# MU3E_ORDERED_PRIORITY_QUEUE register map
Vendor: Mu3e; Series: MU3E_FPGA_IP; File version: 26.5.1.0509
CMSIS-SVD description of the ordered_priority_queue CSR aperture. BaseAddress is 0 because this file describes the relative CSR aperture of the IP; system integration supplies the live slave base address.
Registers are 32-bit, read-only, reset 0x0 unless marked. A register's access mark holds for its fields unless they carry their own. Offsets are from the block's base; lines under a group give offsets from that group; [hi:lo] are bit positions; {n}, {i} and the like mark numbered series; 'fields as' and 'values as' point back to an identical list; <NAME> marks a mode.

## Memory map
0x00000000 ORDERED_PRIORITY_QUEUE_CSR size 0x800 — Relative CSR aperture for the ordered priority queue. Register offsets are byte offsets matching the RTL word-addressed Avalon-MM map multiplied by four.

## ORDERED_PRIORITY_QUEUE_CSR — Relative CSR aperture for the ordered priority queue. Register offsets are byte offsets matching the RTL word-addressed Avalon-MM map multiplied by four.
Base 0x00000000
0x00 UID reset 0x4F50514D — Software-visible IP identifier. Default ASCII "OPQM".
  [31:0] value — Compile-time or integration-time UID word. Default ASCII "OPQM".
0x04 META rw — Read-multiplexed metadata word. Write [1:0] selects VERSION, DATE, GIT, or INSTANCE_ID; reads return the selected page payload.
  [31:0] page_sel_or_payload — Writes use [1:0] as the metadata page selector; reads return the selected 32-bit payload.
0x08 LANE_MASK rw — Software lane mask applied at packet boundaries. Low CAP.N_LANE bits are implemented.
  [15:0] lane_mask — Bit i masks lane i after the in-flight packet drains.
0x0C CTRL wo — Write-only control pulses.
  [0] clear_counters rw write-1-sets — Write one to clear all software-visible counters and sticky handle FIFO overflow status.
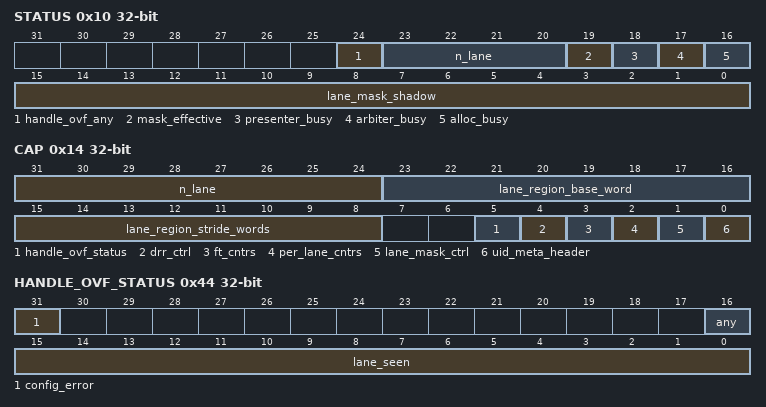
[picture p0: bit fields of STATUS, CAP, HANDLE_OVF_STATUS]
0x10 STATUS — Lane-mask shadow, busy flags, effective-mask status, lane count, and handle FIFO overflow summary.
  [24] handle_ovf_any — Sticky high after any handle FIFO overflow event.
  [23:20] n_lane — Instantiated lane count.
  [19] mask_effective — At least one lane is currently blocked at the packet-boundary mask gate.
  [18] presenter_busy — Egress presenter has a valid beat pending or in flight.
  [17] arbiter_busy — Page-RAM write-port arbiter is active.
  [16] alloc_busy — Page allocator is active.
  [15:0] lane_mask_shadow — Software-programmed lane mask shadow. Only low CAP.N_LANE bits are active.
0x14 CAP — Capability summary and CSR lane-region geometry.
  [31:24] n_lane — Number of instantiated ingress lanes.
  [23:16] lane_region_base_word — Base word address of the per-lane CSR region. Current RTL returns 0x40.
  [15:8] lane_region_stride_words — Per-lane CSR region stride in 32-bit words. Current RTL returns 0x10.
  [5] handle_ovf_status — Handle FIFO overflow status, counters, and max occupancy registers are implemented.
  [4] drr_ctrl — DRR allowance programming and observability are implemented.
  [3] ft_cntrs — Frame-table counters are implemented.
  [2] per_lane_cntrs — Per-lane counters are implemented.
  [1] lane_mask_ctrl — Software lane masking is implemented.
  [0] uid_meta_header — Common Mu3e UID and META header is implemented.
0x20 FT_WR_HDR — Headers committed into frame-table ownership.
  [31:0] value
0x24 FT_WR_SHD — Subheaders committed into frame-table ownership.
  [31:0] value
0x28 FT_WR_HIT — Hits committed into frame-table ownership.
  [31:0] value
0x2C FT_RD_HDR — Headers retired through the egress presenter.
  [31:0] value
0x30 FT_RD_SHD — Subheaders retired through the egress presenter.
  [31:0] value
0x34 FT_RD_HIT — Hits retired through the egress presenter.
  [31:0] value
0x38 FT_DROP_HDR — Headers dropped by frame-table overwrite or overwrite recovery.
  [31:0] value
0x3C FT_DROP_SHD — Subheaders dropped by frame-table overwrite or overwrite recovery.
  [31:0] value
0x40 FT_DROP_HIT — Hits dropped by frame-table overwrite or overwrite recovery.
  [31:0] value
0x44 HANDLE_OVF_STATUS — Sticky handle FIFO overflow summary. Any asserted bit marks invalid OPQ geometry or traffic provisioning; software must stop and reconfigure.
  [31] config_error — Alias of any. Treat asserted value as an invalid configuration for the current run.
  [16] any — Sticky OR of all lane handle FIFO overflow bits.
  [15:0] lane_seen — Bit i is sticky after lane i handle FIFO overflow.
{0x80+4i} HANDLE_OVF_CNT_LANE{i:02} (i=0..15) — Saturating count of handle FIFO overflow or overwrite-risk events for this lane. Any nonzero count is a configuration error for this run.
  [31:0] value — Saturating handle FIFO overflow event count.
{0xC0+4i} HANDLE_OCC_MAX_LANE{i:02} (i=0..15) — Maximum observed handle FIFO occupancy for this lane since reset or CTRL.CLEAR_COUNTERS.
  [31:0] value — Maximum observed handle FIFO occupancy.
{0x100+0x40*i} LANE{i:02}_WR_HDR_CNT (i=0..15) — Headers accepted from ingress parsing. Valid when this lane index is below CAP.N_LANE; otherwise the RTL reads zero.
  [31:0] value — Headers accepted from ingress parsing.
{0x104+0x40*i} LANE{i:02}_WR_SHD_CNT (i=0..15) — Subheaders accepted from ingress parsing. Valid when this lane index is below CAP.N_LANE; otherwise the RTL reads zero.
  [31:0] value — Subheaders accepted from ingress parsing.
{0x108+0x40*i} LANE{i:02}_WR_HIT_CNT (i=0..15) — Hit words written into the lane FIFO. Valid when this lane index is below CAP.N_LANE; otherwise the RTL reads zero.
  [31:0] value — Hit words written into the lane FIFO.
{0x10C+0x40*i} LANE{i:02}_RD_HDR_CNT (i=0..15) — Headers consumed by the page allocator. Valid when this lane index is below CAP.N_LANE; otherwise the RTL reads zero.
  [31:0] value — Headers consumed by the page allocator.
{0x110+0x40*i} LANE{i:02}_RD_SHD_CNT (i=0..15) — Subheaders accepted into the merged page stream. Valid when this lane index is below CAP.N_LANE; otherwise the RTL reads zero.
  [31:0] value — Subheaders accepted into the merged page stream.
{0x114+0x40*i} LANE{i:02}_RD_HIT_CNT (i=0..15) — Hits accepted into the merged page stream. Valid when this lane index is below CAP.N_LANE; otherwise the RTL reads zero.
  [31:0] value — Hits accepted into the merged page stream.
{0x118+0x40*i} LANE{i:02}_DROP_HDR_CNT (i=0..15) — Headers dropped before frame-table ownership. Valid when this lane index is below CAP.N_LANE; otherwise the RTL reads zero.
  [31:0] value — Headers dropped before frame-table ownership.
{0x11C+0x40*i} LANE{i:02}_DROP_SHD_CNT (i=0..15) — Subheaders dropped before frame-table ownership. Valid when this lane index is below CAP.N_LANE; otherwise the RTL reads zero.
  [31:0] value — Subheaders dropped before frame-table ownership.
{0x120+0x40*i} LANE{i:02}_DROP_HIT_CNT (i=0..15) — Hits dropped before frame-table ownership. Valid when this lane index is below CAP.N_LANE; otherwise the RTL reads zero.
  [31:0] value — Hits dropped before frame-table ownership.
{0x124+0x40*i} LANE{i:02}_LANE_FREE_CREDIT (i=0..15) — Live lane-FIFO free-credit word. Valid when this lane index is below CAP.N_LANE; otherwise the RTL reads zero.
  [31:0] value — Live lane-FIFO free-credit word.
{0x128+0x40*i} LANE{i:02}_TICKET_FREE_CREDIT (i=0..15) — Live ticket-FIFO free-credit word. Valid when this lane index is below CAP.N_LANE; otherwise the RTL reads zero.
  [31:0] value — Live ticket-FIFO free-credit word.
{0x12C+0x40*i} LANE{i:02}_DRR_ALLOWANCE rw (i=0..15) — Software-programmed DRR refill allowance in page words. Valid when this lane index is below CAP.N_LANE; otherwise the RTL reads zero.
  [9:0] value — Software-programmed DRR refill allowance in page words.
{0x130+0x40*i} LANE{i:02}_DRR_QUANTUM_LIVE (i=0..15) — Live DRR deficit budget. Valid when this lane index is below CAP.N_LANE; otherwise the RTL reads zero.
  [9:0] value — Live DRR deficit budget.
{0x134+0x40*i} LANE{i:02}_DRR_GRANT_CNT (i=0..15) — Block-level arbiter grant count. Valid when this lane index is below CAP.N_LANE; otherwise the RTL reads zero.
  [31:0] value — Block-level arbiter grant count.
{0x138+0x40*i} LANE{i:02}_DRR_BEAT_CNT (i=0..15) — Page-RAM data beats served from this lane. Valid when this lane index is below CAP.N_LANE; otherwise the RTL reads zero.
  [31:0] value — Page-RAM data beats served from this lane.
{0x13C+0x40*i} LANE{i:02}_DRR_DEFER_CNT (i=0..15) — Defer rounds while this lane requested service without enough budget. Valid when this lane index is below CAP.N_LANE; otherwise the RTL reads zero.
  [31:0] value — Defer rounds while this lane requested service without enough budget.
